# SIM3C164_B register map
File version: 1
CPU: 
Registers are 32-bit, read-write, reset 0x0 unless marked. A register's access mark holds for its fields unless they carry their own. Offsets are from the block's base; [hi:lo] are bit positions; {n}, {i} and the like mark numbered series; 'fields as' and 'values as' point back to an identical list.

## DEVICEID_0
Base 0x400490C0
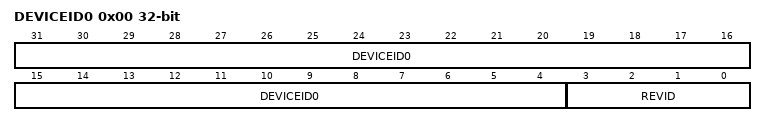
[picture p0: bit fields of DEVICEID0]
0x00 DEVICEID0 — Device ID Word 0
  [31:4] DEVICEID0
  [3:0] REVID — Revision ID.
    0=REVA (Revision A.)
{0x0+0x10*i} DEVICEID{i} (i=1..3) — Device ID Word {i}

## FLASHCTRL_0
Base 0x4002E000
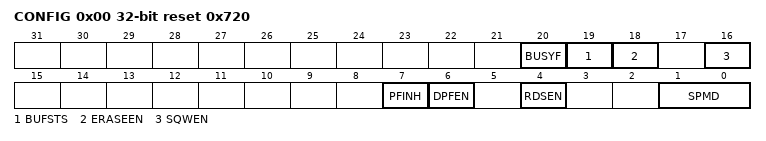
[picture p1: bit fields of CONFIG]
0x00 CONFIG reset 0x720 — Controller Configuration
  [20] BUSYF ro — Flash Operation Busy Flag.
    0=NOT_SET (The Flash interface is not busy.); 1=SET (The Flash interface is busy with an operation.)
  [19] BUFSTS ro — Flash Buffer Status.
    0=EMPTY (The Flash controller write data buffer is empty.); 1=FULL (The Flash controller write data buffer is full.)
  [18] ERASEEN — Flash Page Erase Enable.
    0=DISABLED (Writes to the WRDATA field will initiate a write to Flash at the address in the WRADDR field.); 1=ENABLED (Writes to the WRDATA field will initiate an erase of the Flash page containing the address in the WRADDR field.)
  [16] SQWEN — Flash Write Sequence Enable.
    0=DISABLED (Disable sequential write mode.); 1=ENABLED (Enable sequential write mode.)
  [7] PFINH — Prefetch Inhibit.
    0=INACTIVE (Any reads from Flash are prefetched until the prefetch buffer is full.); 1=ACTIVE (Inhibit the prefetch engine.)
  [6] DPFEN — Data Prefetch Enable.
    0=DISABLED (Data accesses are excluded from the prefetch buffer.); 1=ENABLED (Data accesses are included in the prefetch buffer.)
  [4] RDSEN — Read Store Mode Enable.
    0=DISABLED (Disable read store mode.); 1=ENABLED (Enable read store mode.)
  [1:0] SPMD — Flash Speed Mode.
    {v}=MODE{v} (Read and write the Flash at speed mode {v}.) (v=0..3)
0xA0 WRADDR — Flash Write Address
  [31:0] WRADDR — Flash Write Address.
0xB0 WRDATA — Flash Write Data
  [31:0] WRDATA wo — Flash Write Data.
0xC0 KEY — Flash Modification Key
  [7:0] KEY — Flash Key.
    90=MULTI_LOCK; 165=INITIAL_UNLOCK; 241=SINGLE_UNLOCK; 242=MULTI_UNLOCK
0xD0 TCONTROL reset 0x3005C — Flash Timing Control
  [6] FLRTMD — Flash Read Timing Mode.
    0=SLOW (Configure the Flash read controller for AHB clocks below 20 MHz.); 1=FAST (Configure the Flash read controller for AHB clocks above 20 MHz.)

## IVC_0
Base 0x40044000
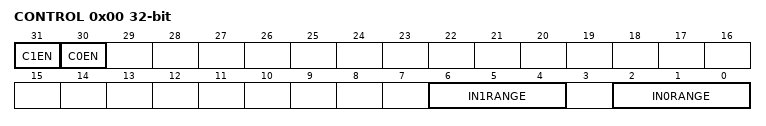
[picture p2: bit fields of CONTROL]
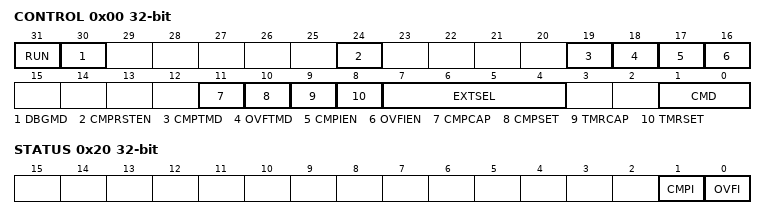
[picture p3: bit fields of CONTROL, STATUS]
0x00 CONTROL — Module Control
  [31] C1EN — Converter 1 Enable.
    0=DISABLED (Disable IVC channel 1.); 1=ENABLED (Enable IVC channel 1.)
  [30] C0EN — Converter 0 Enable.
    0=DISABLED (Disable IVC channel 0.); 1=ENABLED (Enable IVC channel 0.)
  [6:4] IN1RANGE — Input 1 Range.
    0=6_MA (Input range is 0-6 mA.); 1=5_MA (Input range is 0-5 mA.); 2=4_MA (Input range is 0-4 mA.); 3=3_MA (Input range is 0-3 mA.); 4=2_MA (Input range is 0-2 mA.); 5=1_MA (Input range is 0-1 mA.)
  [2:0] IN0RANGE — Input 0 Range.
    values as IN1RANGE

## LPTIMER_0
Base 0x40038000
0x00 CONTROL — Module Control
  [31] RUN — Timer Run Control and Compare Threshold Enable.
    0=STOP (Stop the timer and disable the compare threshold.); 1=START (Start the timer running and enable the compare threshold.)
  [30] DBGMD — Low Power Timer Debug Mode.
    0=RUN (The Low Power Timer module will continue to operate while the core is halted in debug mode.); 1=HALT (A debug breakpoint will cause the Low Power Timer module to halt.)
  [24] CMPRSTEN — Timer Compare Event Reset Enable.
    0=DISABLED (Timer compare events do not reset the timer.); 1=ENABLED (Timer compare events reset the timer.)
  [19] CMPTMD — Timer Compare Event Toggle Mode .
    0=DISABLED (Timer compare events do not toggle the Low Power Timer output.); 1=ENABLED (Timer compare events toggle the Low Power Timer output.)
  [18] OVFTMD — Timer Overflow Toggle Mode.
    0=DISABLED (Timer overflows do not toggle the Low Power Timer output.); 1=ENABLED (Timer overflows toggle the Low Power Timer output.)
  [17] CMPIEN — Timer Compare Event Interrupt Enable.
    0=DISABLED (Disable the timer compare event interrupt.); 1=ENABLED (Enable the timer compare event interrupt.)
  [16] OVFIEN — Timer Overflow Interrupt Enable.
    0=DISABLED (Disable the timer overflow interrupt.); 1=ENABLED (Enable the timer overflow interrupt.)
  [11] CMPCAP — Timer Comparator Capture.
    1=SET (Writing a 1 to CMPCAP initiates a read of the internal comparator register into the DATA register. This field is automatically cleared by hardware when the operation completes and does not need to be cleared by software.)
  [10] CMPSET — Timer Comparator Set.
    1=SET (Writing a 1 to CMPSET initiates a copy of the value in DATA into the internal timer comparator register. This field is automatically cleared by hardware when the copy is complete and does not need to be cleared by software.)
  [9] TMRCAP — Timer Capture.
    1=SET (Writing a 1 to TMRCAP initiates a read of internal timer register into the DATA register. This field is automatically cleared by hardware when the operation completes and does not need to be cleared by software.)
  [8] TMRSET — Timer Set.
    1=SET (Writing a 1 to TMRSET initiates a copy of the value from the DATA register into the internal timer register. This field is automatically cleared by hardware when the copy is complete and does not need to be cleared by software.)
  [7:4] EXTSEL — External Trigger Source Select.
    0=LPTNT0 (Select external trigger LPTnT0 (PB3.0).); 1=LPTNT1 (Select external trigger LPTnT1 (PB3.1).); 2=LPTNT2 (Select external trigger LPTnT2 (PB3.2).); 3=LPTNT3 (Select external trigger LPTnT3 (Comparator 0 Output).); {v}=LPTNT{v} (Select external trigger LPTnT{v} (RESERVED).) (v=4..15)
  [1:0] CMD — Count Mode.
    0=FREE (The timer is free running mode on the RTCn module clock (RTCnOSC or LFOSCn).); 1=RISING_EDGE (The timer is incremented on the rising edges of the selected external trigger (LPTnTx).); 2=FALLING_EDGE (The timer is incremented on the falling edges of the selected external trigger (LPTnTx).); 3=ANY_EDGE (The timer is incremented on both edges of the selected external trigger (LPTnTx).)
0x10 DATA — Timer and Comparator Data
  [15:0] DATA — Timer and Comparator Data.
0x20 STATUS — Module Status
  [1] CMPI — Timer Compare Event Interrupt Flag.
    0=NOT_SET (A timer compare event has not occurred.); 1=SET (A timer compare event occurred.)
  [0] OVFI — Timer Overflow Interrupt Flag.
    0=NOT_SET (A timer overflow has not occurred.); 1=SET (A timer overflow occurred.)
